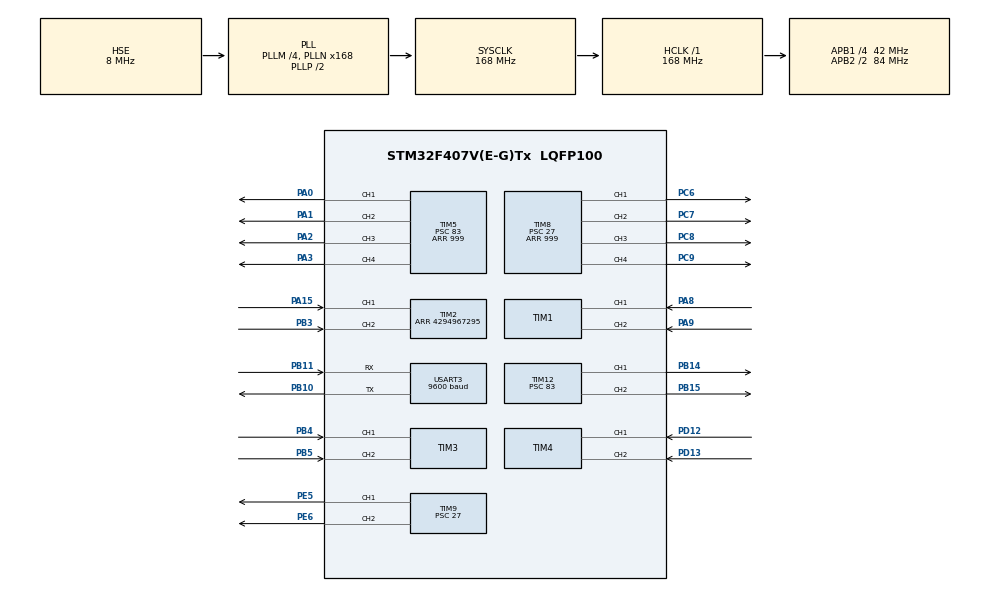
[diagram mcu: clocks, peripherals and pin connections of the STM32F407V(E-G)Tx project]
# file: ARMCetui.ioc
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Dma.Request0=USART3_RX
Dma.Request1=USART3_TX
Dma.USART3_RX.0.Direction=DMA_PERIPH_TO_MEMORY
Dma.USART3_RX.0.FIFOMode=DMA_FIFOMODE_DISABLE
Dma.USART3_RX.0.Instance=DMA1_Stream1
Dma.USART3_RX.0.MemDataAlignment=DMA_MDATAALIGN_BYTE
Dma.USART3_RX.0.MemInc=DMA_MINC_ENABLE
Dma.USART3_RX.0.Mode=DMA_NORMAL
Dma.USART3_RX.0.PeriphDataAlignment=DMA_PDATAALIGN_BYTE
Dma.USART3_RX.0.PeriphInc=DMA_PINC_DISABLE
Dma.USART3_RX.0.Priority=DMA_PRIORITY_LOW
Dma.USART3_TX.1.Direction=DMA_MEMORY_TO_PERIPH
Dma.USART3_TX.1.FIFOMode=DMA_FIFOMODE_DISABLE
Dma.USART3_TX.1.Instance=DMA1_Stream3
Dma.USART3_TX.1.MemDataAlignment=DMA_MDATAALIGN_BYTE
Dma.USART3_TX.1.MemInc=DMA_MINC_ENABLE
Dma.USART3_TX.1.Mode=DMA_NORMAL
Dma.USART3_TX.1.PeriphDataAlignment=DMA_PDATAALIGN_BYTE
Dma.USART3_TX.1.PeriphInc=DMA_PINC_DISABLE
Dma.USART3_TX.1.Priority=DMA_PRIORITY_LOW
Mcu.Family=STM32F4
Mcu.Name=STM32F407V(E-G)Tx
Mcu.Package=LQFP100
NVIC.DMA1_Stream1_IRQn=true\:0\:0\:false\:false\:true\:false\:true\:true
NVIC.DMA1_Stream3_IRQn=true\:0\:0\:false\:false\:true\:false\:true\:true
NVIC.PriorityGroup=NVIC_PRIORITYGROUP_4
NVIC.TIM1_UP_TIM10_IRQn=true\:0\:0\:true\:false\:true\:true\:true\:true
NVIC.TIM2_IRQn=true\:0\:0\:false\:false\:true\:true\:true\:true
NVIC.TIM6_DAC_IRQn=true\:1\:0\:true\:false\:true\:true\:true\:true
NVIC.USART3_IRQn=true\:0\:0\:true\:false\:true\:true\:true\:true
PA0-WKUP.Signal=S_TIM5_CH1
PA1.Signal=S_TIM5_CH2
PA13.Mode=Serial_Wire
PA13.Signal=SYS_JTMS-SWDIO
PA14.Mode=Serial_Wire
PA14.Signal=SYS_JTCK-SWCLK
PA15.Signal=S_TIM2_CH1_ETR
PA2.Signal=S_TIM5_CH3
PA3.Signal=S_TIM5_CH4
PA8.Signal=S_TIM1_CH1
PA9.Signal=S_TIM1_CH2
PB10.Mode=Asynchronous
PB10.Signal=USART3_TX
PB11.Mode=Asynchronous
PB11.Signal=USART3_RX
PB14.Signal=S_TIM12_CH1
PB15.Signal=S_TIM12_CH2
PB3.Signal=S_TIM2_CH2
PB4.Signal=S_TIM3_CH1
PB5.Signal=S_TIM3_CH2
PC14-OSC32_IN.Mode=LSE-External-Oscillator
PC14-OSC32_IN.Signal=RCC_OSC32_IN
PC15-OSC32_OUT.Mode=LSE-External-Oscillator
PC15-OSC32_OUT.Signal=RCC_OSC32_OUT
PC6.Signal=S_TIM8_CH1
PC7.Signal=S_TIM8_CH2
PC8.Signal=S_TIM8_CH3
PC9.Signal=S_TIM8_CH4
PD12.Signal=S_TIM4_CH1
PD13.Signal=S_TIM4_CH2
PE5.Signal=S_TIM9_CH1
PE6.Signal=S_TIM9_CH2
PH0-OSC_IN.Mode=HSE-External-Oscillator
PH0-OSC_IN.Signal=RCC_OSC_IN
PH1-OSC_OUT.Mode=HSE-External-Oscillator
PH1-OSC_OUT.Signal=RCC_OSC_OUT
ProjectManager.HeapSize=0x200
ProjectManager.StackSize=0x400
ProjectManager.TargetToolchain=MDK-ARM V5.32
RCC.48MHZClocksFreq_Value=84000000
RCC.AHBFreq_Value=168000000
RCC.APB1CLKDivider=RCC_HCLK_DIV4
RCC.APB1Freq_Value=42000000
RCC.APB1TimFreq_Value=84000000
RCC.APB2CLKDivider=RCC_HCLK_DIV2
RCC.APB2Freq_Value=84000000
RCC.APB2TimFreq_Value=168000000
RCC.CortexFreq_Value=168000000
RCC.HCLKFreq_Value=168000000
RCC.HSE_VALUE=8000000
RCC.HSI_VALUE=16000000
RCC.PLLM=4
RCC.PLLN=168
RCC.PLLSourceVirtual=RCC_PLLSOURCE_HSE
RCC.SYSCLKFreq_VALUE=168000000
RCC.SYSCLKSource=RCC_SYSCLKSOURCE_PLLCLK
RCC.VCOOutputFreq_Value=336000000
SH.S_TIM12_CH1.0=TIM12_CH1,PWM Generation1 CH1
SH.S_TIM12_CH2.0=TIM12_CH2,PWM Generation2 CH2
SH.S_TIM1_CH1.0=TIM1_CH1,Encoder_Interface
SH.S_TIM1_CH2.0=TIM1_CH2,Encoder_Interface
SH.S_TIM2_CH1_ETR.0=TIM2_CH1,Encoder_Interface
SH.S_TIM2_CH2.0=TIM2_CH2,Encoder_Interface
SH.S_TIM3_CH1.0=TIM3_CH1,Encoder_Interface
SH.S_TIM3_CH2.0=TIM3_CH2,Encoder_Interface
SH.S_TIM4_CH1.0=TIM4_CH1,Encoder_Interface
SH.S_TIM4_CH2.0=TIM4_CH2,Encoder_Interface
SH.S_TIM5_CH1.0=TIM5_CH1,PWM Generation1 CH1
SH.S_TIM5_CH2.0=TIM5_CH2,PWM Generation2 CH2
SH.S_TIM5_CH3.0=TIM5_CH3,PWM Generation3 CH3
SH.S_TIM5_CH4.0=TIM5_CH4,PWM Generation4 CH4
SH.S_TIM8_CH1.0=TIM8_CH1,PWM Generation1 CH1
SH.S_TIM8_CH2.0=TIM8_CH2,PWM Generation2 CH2
SH.S_TIM8_CH3.0=TIM8_CH3,PWM Generation3 CH3
SH.S_TIM8_CH4.0=TIM8_CH4,PWM Generation4 CH4
SH.S_TIM9_CH1.0=TIM9_CH1,PWM Generation1 CH1
SH.S_TIM9_CH2.0=TIM9_CH2,PWM Generation2 CH2
TIM1.EncoderMode=TIM_ENCODERMODE_TI12
TIM12.Channel-PWM\ Generation1\ CH1=TIM_CHANNEL_1
TIM12.Channel-PWM\ Generation2\ CH2=TIM_CHANNEL_2
TIM12.Period=19999
TIM12.Prescaler=83
TIM2.EncoderMode=TIM_ENCODERMODE_TI12
TIM2.Period=4294967295
TIM5.Channel-PWM\ Generation1\ CH1=TIM_CHANNEL_1
TIM5.Channel-PWM\ Generation2\ CH2=TIM_CHANNEL_2
TIM5.Channel-PWM\ Generation3\ CH3=TIM_CHANNEL_3
TIM5.Channel-PWM\ Generation4\ CH4=TIM_CHANNEL_4
TIM5.Period=999
TIM5.Prescaler=83
TIM6.Period=49
TIM6.Prescaler=1679
TIM8.Channel-PWM\ Generation1\ CH1=TIM_CHANNEL_1
TIM8.Channel-PWM\ Generation2\ CH2=TIM_CHANNEL_2
TIM8.Channel-PWM\ Generation3\ CH3=TIM_CHANNEL_3
TIM8.Channel-PWM\ Generation4\ CH4=TIM_CHANNEL_4
TIM8.Period=999
TIM8.Prescaler=27
TIM9.Channel-PWM\ Generation1\ CH1=TIM_CHANNEL_1
TIM9.Channel-PWM\ Generation2\ CH2=TIM_CHANNEL_2
TIM9.Period=999
TIM9.Prescaler=27
USART3.BaudRate=9600
USART3.VirtualMode=VM_ASYNC
VP_TIM12_VS_ClockSourceINT.Mode=Internal
VP_TIM5_VS_ClockSourceINT.Mode=Internal
VP_TIM6_VS_ClockSourceINT.Mode=Enable_Timer
VP_TIM8_VS_ClockSourceINT.Mode=Internal
VP_TIM9_VS_ClockSourceINT.Mode=Internal
board=custom

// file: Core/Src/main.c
/* USER CODE BEGIN Header */
/**
  ******************************************************************************
  * @file           : main.c
  * @brief          : Main program body
  ******************************************************************************
  * @attention
  *
  * Copyright (c) 2024 STMicroelectronics.
  * All rights reserved.
  *
  * This software is licensed under terms that can be found in the LICENSE file
  * in the root directory of this software component.
  * If no LICENSE file comes with this software, it is provided AS-IS.
  *
  ******************************************************************************
  */
/* USER CODE END Header */
#include "main.h"
#include "dma.h"
#include "tim.h"
#include "usart.h"
#include "gpio.h"

/* USER CODE BEGIN Includes */
#include "App.h"

/* USER CODE END Includes */

void SystemClock_Config(void);

int main(void)
{

  /* MCU Configuration--------------------------------------------------------*/

  /* Reset of all peripherals, Initializes the Flash interface and the Systick. */
  HAL_Init();

  /* Configure the system clock */
  SystemClock_Config();

  /* USER CODE BEGIN SysInit */
	protocol_init();
  /* USER CODE END SysInit */

  /* Initialize all configured peripherals */
  MX_GPIO_Init();
  MX_DMA_Init();
  MX_TIM2_Init();
  MX_TIM5_Init();
  MX_TIM6_Init();
  MX_USART3_UART_Init();
  MX_TIM12_Init();
  MX_TIM1_Init();
  MX_TIM3_Init();
  MX_TIM4_Init();
  MX_TIM8_Init();
  MX_TIM9_Init();
  /* USER CODE BEGIN 2 */
	system_init();  //系统初始化
  /* USER CODE END 2 */

  /* Infinite loop */
  while (1)
  {

    /* USER CODE BEGIN 3 */

	motor_cetui_set_postion(Ce_Speed);
	HAL_Delay(10);

  }
  /* USER CODE END 3 */
}

void SystemClock_Config(void)
{
  RCC_OscInitTypeDef RCC_OscInitStruct = {0};
  RCC_ClkInitTypeDef RCC_ClkInitStruct = {0};

  /** Configure the main internal regulator output voltage
  */
  __HAL_RCC_PWR_CLK_ENABLE();
  __HAL_PWR_VOLTAGESCALING_CONFIG(PWR_REGULATOR_VOLTAGE_SCALE1);

  /** Initializes the RCC Oscillators according to the specified parameters
  * in the RCC_OscInitTypeDef structure.
  */
  RCC_OscInitStruct.OscillatorType = RCC_OSCILLATORTYPE_HSE;
  RCC_OscInitStruct.HSEState = RCC_HSE_ON;
  RCC_OscInitStruct.PLL.PLLState = RCC_PLL_ON;
  RCC_OscInitStruct.PLL.PLLSource = RCC_PLLSOURCE_HSE;
  RCC_OscInitStruct.PLL.PLLM = 4;
  RCC_OscInitStruct.PLL.PLLN = 168;
  RCC_OscInitStruct.PLL.PLLP = RCC_PLLP_DIV2;
  RCC_OscInitStruct.PLL.PLLQ = 4;
  if (HAL_RCC_OscConfig(&RCC_OscInitStruct) != HAL_OK)
  {
    Error_Handler();
  }

  /** Initializes the CPU, AHB and APB buses clocks
  */
  RCC_ClkInitStruct.ClockType = RCC_CLOCKTYPE_HCLK|RCC_CLOCKTYPE_SYSCLK
                              |RCC_CLOCKTYPE_PCLK1|RCC_CLOCKTYPE_PCLK2;
  RCC_ClkInitStruct.SYSCLKSource = RCC_SYSCLKSOURCE_PLLCLK;
  RCC_ClkInitStruct.AHBCLKDivider = RCC_SYSCLK_DIV1;
  RCC_ClkInitStruct.APB1CLKDivider = RCC_HCLK_DIV4;
  RCC_ClkInitStruct.APB2CLKDivider = RCC_HCLK_DIV2;

  if (HAL_RCC_ClockConfig(&RCC_ClkInitStruct, FLASH_LATENCY_5) != HAL_OK)
  {
    Error_Handler();
  }
}

void Error_Handler(void)
{
  __disable_irq();
  while (1)
  {
  }
}
